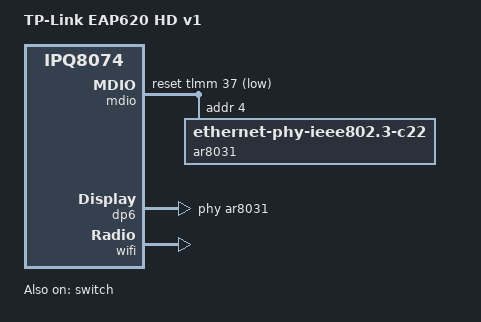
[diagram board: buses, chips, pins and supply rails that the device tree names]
// SPDX-License-Identifier: GPL-2.0-or-later OR MIT

/dts-v1/;

#include "ipq8072-tplink.dtsi"

/ {
	model = "TP-Link EAP620 HD v1";
	compatible = "tplink,eap620hd-v1", "qcom,ipq8074";
};

&mdio {
	status = "okay";

	pinctrl-0 = <&mdio_pins>;
	pinctrl-names = "default";
	reset-gpios = <&tlmm 37 GPIO_ACTIVE_LOW>;

	ar8031: ethernet-phy@4 {
		compatible = "ethernet-phy-ieee802.3-c22";
		reg = <4>;
	};
};

&dp6 {
	status = "okay";
	phy-handle = <&ar8031>;
	label = "lan";
};

&switch {
	status = "okay";
	switch_lan_bmp = <ESS_PORT6>;
	switch_mac_mode2 = <MAC_MODE_SGMII_PLUS>;

	qcom,port_phyinfo {
		port@6 {
			phy_address = <4>;
			port_id = <6>;
		};
	};
};

&wifi {
	status = "okay";
	qcom,ath11k-fw-memory-mode = <1>;
	qcom,ath11k-calibration-variant = "TP-Link-EAP620-HD-v1";
};

&edma {
	status = "okay";
};
